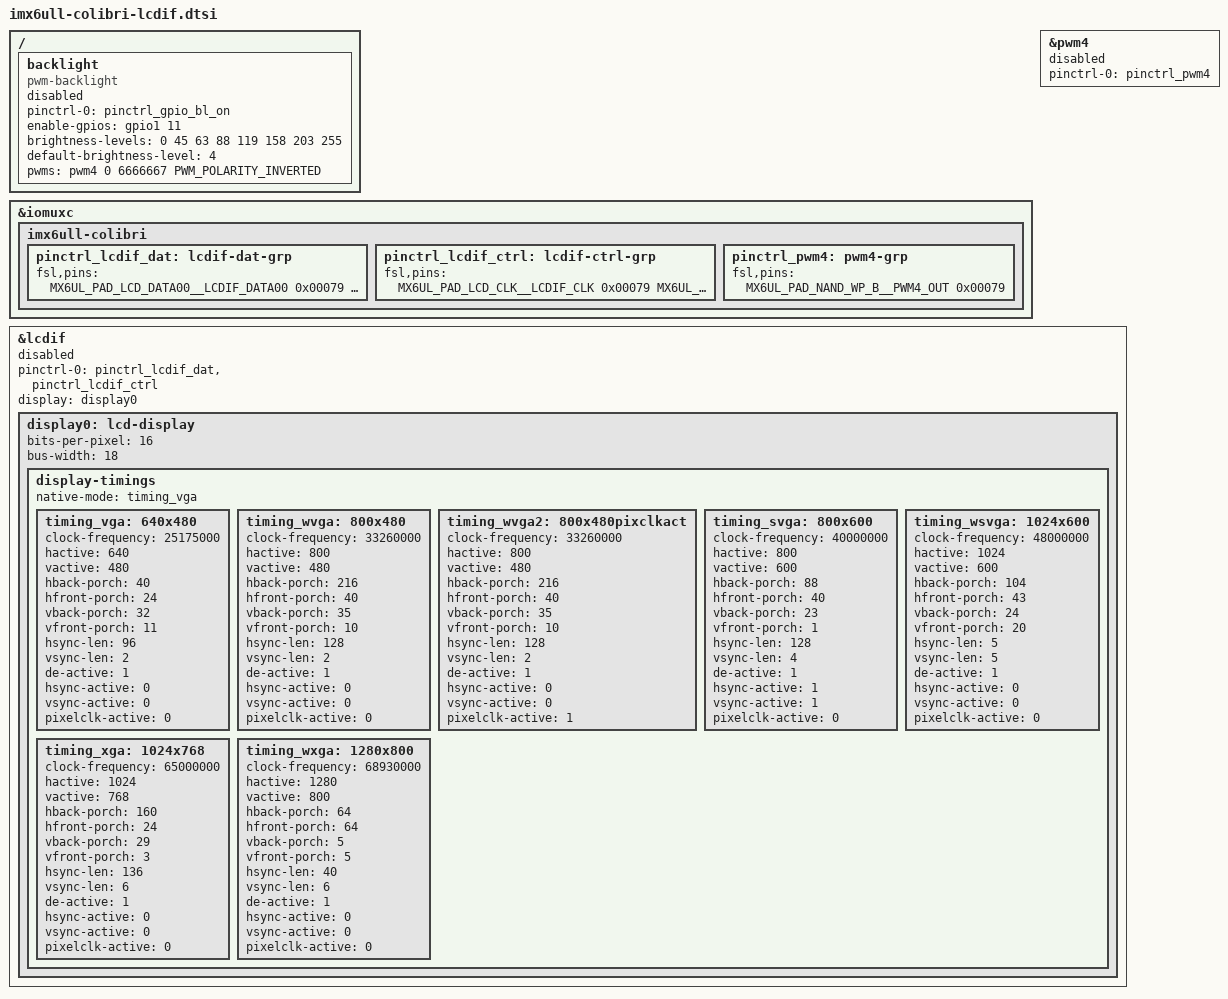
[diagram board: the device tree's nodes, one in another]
// SPDX-License-Identifier: (GPL-2.0 OR MIT)
/*
 * Copyright 2021 Toradex AG
 */
#include "imx6ull.dtsi"
#include <dt-bindings/pwm/pwm.h>

/ {
	backlight: backlight {
		compatible = "pwm-backlight";
		pinctrl-names = "default";
		pinctrl-0 = <&pinctrl_gpio_bl_on>;
		enable-gpios = <&gpio1 11 GPIO_ACTIVE_HIGH>;
		brightness-levels = <0 45 63 88 119 158 203 255>;
		default-brightness-level = <4>;
		pwms = <&pwm4 0 6666667 PWM_POLARITY_INVERTED>;
		status = "disabled";
	};
};

&iomuxc {
	imx6ull-colibri {
		pinctrl_lcdif_dat: lcdif-dat-grp {
			fsl,pins = <
				MX6UL_PAD_LCD_DATA00__LCDIF_DATA00 	0x00079	/* SODIMM 76 */
				MX6UL_PAD_LCD_DATA01__LCDIF_DATA01	0x00079	/* SODIMM 70 */
				MX6UL_PAD_LCD_DATA02__LCDIF_DATA02	0x00079	/* SODIMM 60 */
				MX6UL_PAD_LCD_DATA03__LCDIF_DATA03	0x00079	/* SODIMM 58 */
				MX6UL_PAD_LCD_DATA04__LCDIF_DATA04	0x00079	/* SODIMM 78 */
				MX6UL_PAD_LCD_DATA05__LCDIF_DATA05	0x00079	/* SODIMM 72 */
				MX6UL_PAD_LCD_DATA06__LCDIF_DATA06	0x00079	/* SODIMM 80 */
				MX6UL_PAD_LCD_DATA07__LCDIF_DATA07	0x00079	/* SODIMM 46 */
				MX6UL_PAD_LCD_DATA08__LCDIF_DATA08	0x00079	/* SODIMM 62 */
				MX6UL_PAD_LCD_DATA09__LCDIF_DATA09	0x00079	/* SODIMM 48 */
				MX6UL_PAD_LCD_DATA10__LCDIF_DATA10	0x00079	/* SODIMM 74 */
				MX6UL_PAD_LCD_DATA11__LCDIF_DATA11	0x00079	/* SODIMM 50 */
				MX6UL_PAD_LCD_DATA12__LCDIF_DATA12	0x00079	/* SODIMM 52 */
				MX6UL_PAD_LCD_DATA13__LCDIF_DATA13	0x00079	/* SODIMM 54 */
				MX6UL_PAD_LCD_DATA14__LCDIF_DATA14	0x00079	/* SODIMM 66 */
				MX6UL_PAD_LCD_DATA15__LCDIF_DATA15	0x00079	/* SODIMM 64 */
				MX6UL_PAD_LCD_DATA16__LCDIF_DATA16	0x00079	/* SODIMM 57 */
				MX6UL_PAD_LCD_DATA17__LCDIF_DATA17	0x00079	/* SODIMM 61 */
			>;
		};

		pinctrl_lcdif_ctrl: lcdif-ctrl-grp {
			fsl,pins = <
				MX6UL_PAD_LCD_CLK__LCDIF_CLK	    0x00079	/* SODIMM 56 */
				MX6UL_PAD_LCD_ENABLE__LCDIF_ENABLE  0x00079	/* SODIMM 44 */
				MX6UL_PAD_LCD_HSYNC__LCDIF_HSYNC    0x00079	/* SODIMM 68 */
				MX6UL_PAD_LCD_VSYNC__LCDIF_VSYNC    0x00079	/* SODIMM 82 */
			>;
		};

		pinctrl_pwm4: pwm4-grp {
			fsl,pins = <
				MX6UL_PAD_NAND_WP_B__PWM4_OUT	0x00079		/* SODIMM 59 */
			>;
		};
	}; /* imx6ull-colibri { */
};

&pwm4 {
	pinctrl-names = "default";
	pinctrl-0 = <&pinctrl_pwm4>;
	#pwm-cells = <3>;
	status = "disabled";
};

&lcdif {
	pinctrl-names = "default";
	pinctrl-0 = <&pinctrl_lcdif_dat
		     &pinctrl_lcdif_ctrl>;

	display = <&display0>;
	status = "disabled";

	display0: lcd-display {
		bits-per-pixel = <16>;
		bus-width = <18>;

		display-timings {
			native-mode = <&timing_vga>;

			/* Standard VGA timing */
			timing_vga: 640x480 {
				clock-frequency = <25175000>;
				hactive = <640>;
				vactive = <480>;
				hback-porch = <40>;
				hfront-porch = <24>;
				vback-porch = <32>;
				vfront-porch = <11>;
				hsync-len = <96>;
				vsync-len = <2>;
				de-active = <1>;
				hsync-active = <0>;
				vsync-active = <0>;
				pixelclk-active = <0>;
			};

			/* WVGA Timing, e.g. EDT ET070080DH6 */
			timing_wvga: 800x480 {
				clock-frequency = <33260000>;
				hactive = <800>;
				vactive = <480>;
				hback-porch = <216>;
				hfront-porch = <40>;
				vback-porch = <35>;
				vfront-porch = <10>;
				hsync-len = <128>;
				vsync-len = <2>;
				de-active = <1>;
				hsync-active = <0>;
				vsync-active = <0>;
				pixelclk-active = <0>;
			};
			/* WVGA Timing, TouchRevolution Fusion 7" */
			timing_wvga2: 800x480pixclkact {
				clock-frequency = <33260000>;
				hactive = <800>;
				vactive = <480>;
				hback-porch = <216>;
				hfront-porch = <40>;
				vback-porch = <35>;
				vfront-porch = <10>;
				hsync-len = <128>;
				vsync-len = <2>;
				de-active = <1>;
				hsync-active = <0>;
				vsync-active = <0>;
				pixelclk-active = <1>;
			};
			/* Standard SVGA timing */
			timing_svga: 800x600 {
				clock-frequency = <40000000>;
				hactive = <800>;
				vactive = <600>;
				hback-porch = <88>;
				hfront-porch = <40>;
				vback-porch = <23>;
				vfront-porch = <1>;
				hsync-len = <128>;
				vsync-len = <4>;
				de-active = <1>;
				hsync-active = <1>;
				vsync-active = <1>;
				pixelclk-active = <0>;
			};
			/* TouchRevolution Fusion 10"/CLAA101NC05 10.1 inch */
			timing_wsvga: 1024x600 {
				clock-frequency = <48000000>;
				hactive = <1024>;
				vactive = <600>;
				hback-porch = <104>;
				hfront-porch = <43>;
				vback-porch = <24>;
				vfront-porch = <20>;
				hsync-len = <5>;
				vsync-len = <5>;
				de-active = <1>;
				hsync-active = <0>;
				vsync-active = <0>;
				pixelclk-active = <0>;
			};
			/* Standard XGA timing */
			timing_xga: 1024x768 {
				clock-frequency = <65000000>;
				hactive = <1024>;
				vactive = <768>;
				hback-porch = <160>;
				hfront-porch = <24>;
				vback-porch = <29>;
				vfront-porch = <3>;
				hsync-len = <136>;
				vsync-len = <6>;
				de-active = <1>;
				hsync-active = <0>;
				vsync-active = <0>;
				pixelclk-active = <0>;
			};
			/* WXGA Timing, LT170410 display 10" */
			timing_wxga: 1280x800 {
				clock-frequency = <68930000>;
				hactive = <1280>;
				vactive = <800>;
				hback-porch = <64>;
				hfront-porch = <64>;
				vback-porch = <5>;
				vfront-porch = <5>;
				hsync-len = <40>;
				vsync-len = <6>;
				de-active = <1>;
				hsync-active = <0>;
				vsync-active = <0>;
				pixelclk-active = <0>;
			};
		};
	};
};
